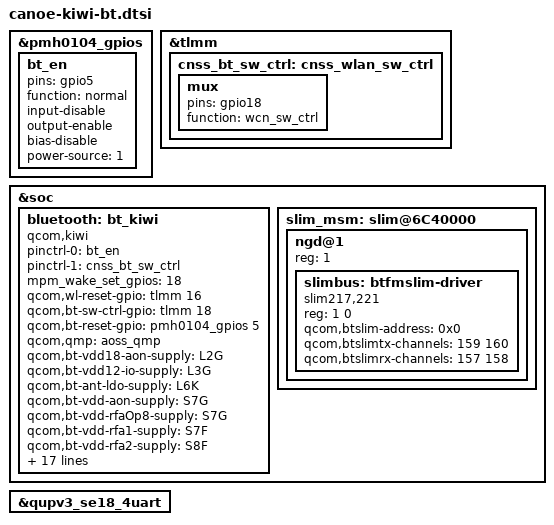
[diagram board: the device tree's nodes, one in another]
// SPDX-License-Identifier: BSD-3-Clause

/*
 * Copyright (c) 2024 Qualcomm Innovation Center, Inc. All rights reserved.
 */

#include <dt-bindings/interconnect/qcom,canoe.h>
#include <dt-bindings/clock/qcom,rpmh.h>

&pmh0104_gpios {
	bt_en: bt_en {
		pins = "gpio5";
		function = "normal";
		input-disable;
		output-enable;
		bias-disable;
		power-source = <1>;
	};
};

&tlmm {
	cnss_bt_sw_ctrl: cnss_wlan_sw_ctrl {
		mux {
			pins = "gpio18";
			function = "wcn_sw_ctrl";
		};
	};
};

&soc {
	bluetooth: bt_kiwi {
			compatible = "qcom,kiwi";
        		pinctrl-names = "bt_en", "sw_ctrl";
			pinctrl-0 = <&bt_en>;
			pinctrl-1 = <&cnss_bt_sw_ctrl>;
			/* List of GPIOs to be setup for interrupt wakeup capable*/
			mpm_wake_set_gpios = <18>;
			qcom,wl-reset-gpio = <&tlmm 16 0>; /* WL_EN */
			qcom,bt-sw-ctrl-gpio = <&tlmm 18 0>; /* SW_CTRL */
			qcom,bt-reset-gpio = <&pmh0104_gpios 5 0>; /* BT_EN */
			qcom,qmp = <&aoss_qmp>;

			qcom,bt-vdd18-aon-supply  = <&L2G>;  /* BT VDD1.8 AON */
			qcom,bt-vdd12-io-supply   = <&L3G>;  /* BT VDD1.2V IO */
			qcom,bt-ant-ldo-supply    = <&L6K>;  /* BT ANT - AV91C_VDD */
			qcom,bt-vdd-aon-supply    = <&S7G>;  /* BT AON LDO*/
			qcom,bt-vdd-rfaOp8-supply = <&S7G>;  /* BT RFAOp8 CMN LDO*/
			qcom,bt-vdd-rfa1-supply   = <&S7F>;  /* BT RFA1.2 LDO */
			qcom,bt-vdd-rfa2-supply   = <&S8F>;  /* BT RFA1.8 LDO */

			qcom,bt-vdd18-aon-config  = <1800000 1800000 30000 1 0>;
			qcom,bt-vdd12-io-config   = <1200000 1200000 30000 1 0>;
			qcom,bt-ant-ldo-config    = <1800000 2000000 0 1 0>;
			qcom,bt-vdd-aon-config    = <916000 1100000 0 1 0>;
			qcom,bt-vdd-rfaOp8-config = <916000 1100000 0 1 0>;
			qcom,bt-vdd-rfa1-config   = <1316000 1400000 0 1 0>;
			qcom,bt-vdd-rfa2-config   = <1864000 2000000 0 1 0>;

        		qcom,pdc_init_table =
        			"{class: wlan_pdc, ss: rf, res: S8F0.v, upval: 1900}",
        			"{class: wlan_pdc, ss: rf, res: S8F0.v, dwnval: 1860}",
        			"{class: wlan_pdc, ss: rf, res: S7F0.v, upval: 1352}",
        			"{class: wlan_pdc, ss: rf, res: S7F0.v, dwnval: 988}",
        			"{class: wlan_pdc, ss: rf, res: S7G0.m, enable: 1}",
        			"{class: wlan_pdc, ss: rf, res: S7G0.v, enable: 1}";

	};

	slim_msm: slim@6C40000 {
		status =  "ok";
		ngd@1 {
			reg = <1>;
			#address-cells = <1>;
			#size-cells = <1>;
			//slimbus child nodes
			slimbus: btfmslim-driver {
				compatible = "slim217,221";
				reg = <1 0>;
				qcom,btslim-address  = <0x0>;
				qcom,btslimtx-channels = <159 160>;
				qcom,btslimrx-channels = <157 158>;
			};
		};
	};

};


//uart instance
&qupv3_se18_4uart {
	status = "ok";
};
